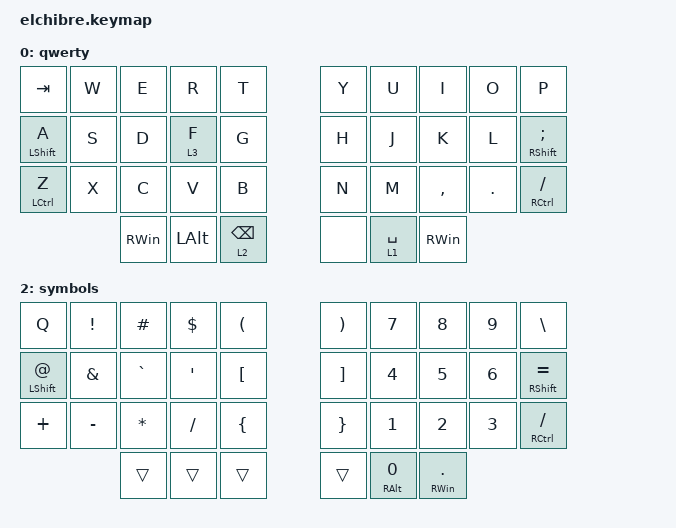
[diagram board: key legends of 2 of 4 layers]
#include <behaviors.dtsi>
#include <dt-bindings/zmk/bt.h>
#include <dt-bindings/zmk/keys.h>
#include <dt-bindings/zmk/outputs.h>

&lt {
    tapping-term-ms = <160>;
    flavor = "balanced";
};

&mt {
    tapping-term-ms = <160>;
    flavor = "balanced";
};

/ {
    combos {
        compatible = "zmk,combos";
        combo_esc {
            timeout-ms = <25>;
            key-positions = <0 1>;
            bindings = <&kp ESC>;
        };
        combo_delete {
            timeout-ms = <25>;
            key-positions = <8 9>;
            bindings = <&kp DEL>;
        };
        combo_enter {
            timeout-ms = <25>;
            key-positions = <17 18>;
            bindings = <&kp ENTER>;
        };
        combo_backspace {
            timeout-ms = <25>;
            key-positions = <11 12>;
            bindings = <&kp BACKSPACE>;
        };
    };
};

/ {
    keymap {
        compatible = "zmk,keymap";

        qwerty {
            bindings = <
                &kp TAB      &kp W  &kp E    &kp R    &kp T           &kp Y           &kp U        &kp I     &kp O      &kp P
                &mt LSHIFT A &kp S  &kp D    &lt 3 F  &kp G           &kp H           &kp J        &kp K     &kp L      &mt RSHIFT SEMI
                &mt LCTRL Z  &kp X  &kp C    &kp V    &kp B           &kp N           &kp M        &kp COMMA &kp PERIOD &mt RCTRL SLASH
                                    &kp RWIN &kp LALT &lt 2 BACKSPACE &none             &lt 1 SPACE  &kp RWIN
            >;
        };

        function {
            bindings = <
                &trans    &kp F7 &kp F8 &kp F9 &kp F12          &bt BT_CLR_ALL &trans &trans &trans &bootloader
                &kp LSHFT &kp F4 &kp F5 &kp F6 &kp F11          &trans &trans &trans &trans &kp RSHIFT
                &kp LCTRL &kp F1 &kp F2 &kp F3 &kp F10          &trans &trans &trans &trans &kp RCTRL
                              &trans         &trans             &trans         &trans
            >;
        };

        symbols {
            bindings = <
                &kp Q         &kp EXCL &kp HASH &kp DLLR &kp LPAR       &kp RPAR &kp N7      &kp N8          &kp N9 &kp BSLH
                &mt LSHIFT AT &kp AMPS &kp GRAVE &kp SQT &kp LBKT       &kp RBKT &kp N4      &kp N5          &kp N6 &mt RSHIFT EQUAL
                &kp PLUS  &kp MINUS &kp STAR &kp SLASH &kp LBRC       &kp RBRC &kp N1      &kp N2          &kp N3 &mt RCTRL SLASH
                                       &trans  &trans  &trans     &trans   &mt RALT N0 &mt RWIN PERIOD
            >;
        };

        navigation {
            bindings = <
                &trans    &kp C_VOL_DN &kp C_VOL_UP &trans &trans          &kp INS   &kp HOME     &kp UP   &kp END   &trans
                &kp LSHFT &kp C_PREV   &kp C_NEXT   &trans &trans          &kp PG_UP &kp LEFT     &kp DOWN &kp RIGHT &kp RSHFT
                &kp LCTRL &trans       &trans       &trans &trans          &kp PG_DN &kp LC(LEFT) &trans   &kp LC(RIGHT)    &kp RCTRL
                                       &trans              &kp DEL         &none       &kp ENTER    &trans
            >;
        };
    };
};
